# HDSC_HC32L130F8UA register map
Vendor: HDSC Co.Ltd; Series: ARMCM0P; File version: 1.2
CPU: CM0 r0p0, little endian, no MPU, no FPU, 3 interrupt priority bits
Registers are 32-bit, read-write, reset 0x0 unless marked. A register's access mark holds for its fields unless they carry their own. Offsets are from the block's base; [hi:lo] are bit positions; {n}, {i} and the like mark numbered series; 'fields as' and 'values as' point back to an identical list.

## DMAC
Base 0x40021000
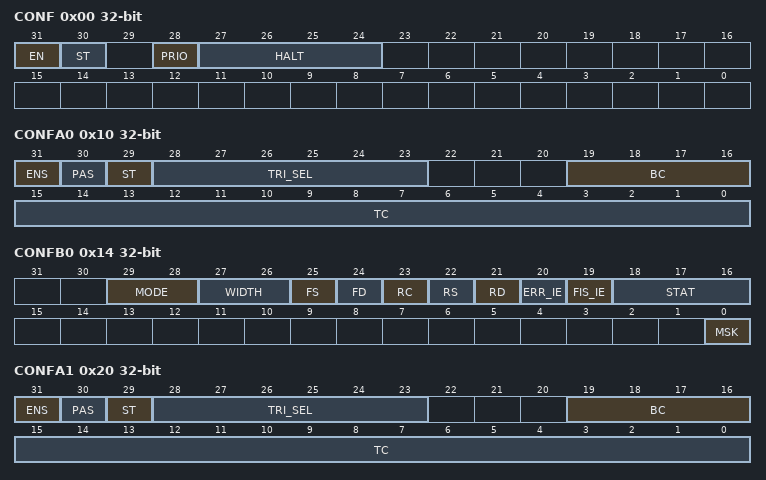
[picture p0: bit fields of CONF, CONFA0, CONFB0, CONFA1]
0x00 CONF
  [31] EN, [30] ST, [28] PRIO, [27:24] HALT
0x10 CONFA0
  [31] ENS, [30] PAS, [29] ST, [28:23] TRI_SEL, [19:16] BC, [15:0] TC
0x14 CONFB0
  [29:28] MODE, [27:26] WIDTH, [25] FS, [24] FD, [23] RC, [22] RS, [21] RD, [20] ERR_IE, [19] FIS_IE, [18:16] STAT, [0] MSK
0x18 SRCADR0
  [31:0] SRCADR
0x1C DSTADR0
  [31:0] DSTADR
0x20 CONFA1
  [31] ENS, [30] PAS, [29] ST, [28:23] TRI_SEL, [19:16] BC, [15:0] TC
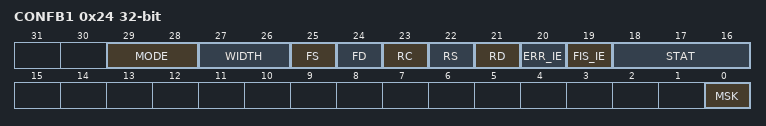
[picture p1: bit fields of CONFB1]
0x24 CONFB1
  fields as CONFB0
0x28 SRCADR1
  [31:0] SRCADR
0x2C DSTADR1
  [31:0] DSTADR

## FLASH
Base 0x40020000
0x00 TNVS reset 0x20
  [8:0] TNVS
0x04 TPGS reset 0x17
  [7:0] TPGS
0x08 TPROG reset 0x1B (reset mask 0xFF)
  [8:0] TPROG
0x0C TSERASE reset 0x4650
  [17:0] TSERASE
0x10 TMERASE reset 0x222E0
  [20:0] TMERASE
0x14 TPRCV reset 0x18
  [11:0] TPRCV
0x18 TSRCV reset 0xF0
  [11:0] TSRCV
0x1C TMRCV reset 0x3E8
  [12:0] TMRCV
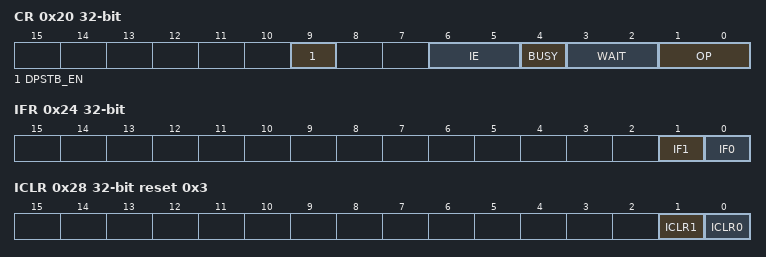
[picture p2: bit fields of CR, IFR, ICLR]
0x20 CR (reset mask 0x277)
  [9] DPSTB_EN, [6:5] IE, [4] BUSY ro, [3:2] WAIT, [1:0] OP
0x24 IFR ro
  [1] IF1, [0] IF0
0x28 ICLR wo reset 0x3
  [1] ICLR1, [0] ICLR0
0x2C BYPASS wo
  [15:0] BYSEQ
0x30 SLOCK

## HDIV
Base 0x40021800
0x00 DIVIDEND
0x04 DIVISOR reset 0x1
  [15:0] DIVISOR
0x08 QUOTIENT
0x0C REMAINDER
0x10 SIGN
  [0] SIGN
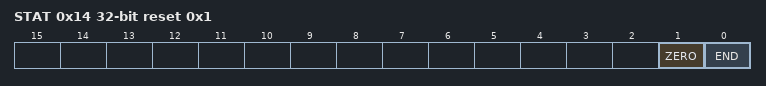
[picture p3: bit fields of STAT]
0x14 STAT reset 0x1
  [1] ZERO ro, [0] END ro

## I2C0 — desc I2C
Base 0x40000400
Same registers: I2C1 0x40004400
0x00 TMRUN
  [0] TME
0x04 TM
  [7:0] TM
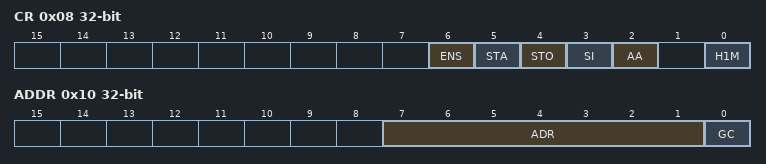
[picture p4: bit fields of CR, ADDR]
0x08 CR
  [6] ENS, [5] STA, [4] STO, [3] SI, [2] AA, [0] H1M
0x0C DATA
  [7:0] DAT
0x10 ADDR
  [7:1] ADR, [0] GC
0x14 STAT ro
  [7:0] STA

## LPTIMER
Base 0x40000F00
0x00 CNT ro
  [15:0] CNT
0x04 ARR
  [15:0] ARR
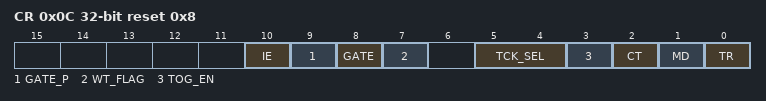
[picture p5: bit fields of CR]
0x0C CR reset 0x8
  [10] IE, [9] GATE_P, [8] GATE, [7] WT_FLAG ro, [5:4] TCK_SEL, [3] TOG_EN, [2] CT, [1] MD, [0] TR
0x10 IFR ro
  [0] TF
0x14 ICLR wo reset 0x1
  [0] TFC

## LPUART0 — desc LPUART
Base 0x40000200
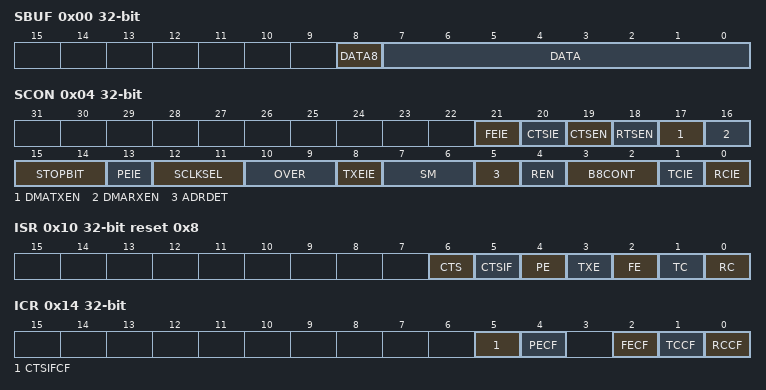
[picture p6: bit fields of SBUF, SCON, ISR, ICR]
0x00 SBUF
  [8] DATA8, [7:0] DATA
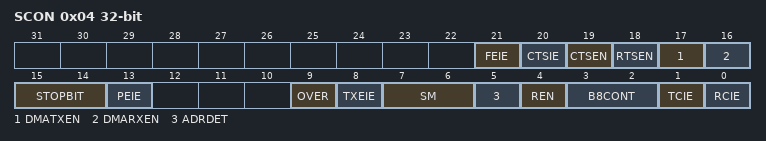
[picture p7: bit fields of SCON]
0x04 SCON
  [21] FEIE, [20] CTSIE, [19] CTSEN, [18] RTSEN, [17] DMATXEN, [16] DMARXEN, [15:14] STOPBIT, [13] PEIE, [12:11] SCLKSEL, [10:9] OVER, [8] TXEIE, [7:6] SM, [5] ADRDET, [4] REN, [3:2] B8CONT, [1] TCIE, [0] RCIE
0x08 SADDR
  [7:0] SADDR
0x0C SADEN
  [7:0] SADEN
0x10 ISR ro reset 0x8
  [6] CTS, [5] CTSIF, [4] PE, [3] TXE, [2] FE, [1] TC, [0] RC
0x14 ICR wo
  [5] CTSIFCF, [4] PECF, [2] FECF, [1] TCCF, [0] RCCF
0x18 SCNT
  [15:0] SCNT

## UART0 — desc UART
Base 0x40000000
Same registers: UART1 0x40000100
Registers as LPUART0; these are added or differ:
0x04 SCON
  [21] FEIE, [20] CTSIE, [19] CTSEN, [18] RTSEN, [17] DMATXEN, [16] DMARXEN, [15:14] STOPBIT, [13] PEIE, [9] OVER, [8] TXEIE, [7:6] SM, [5] ADRDET, [4] REN, [3:2] B8CONT, [1] TCIE, [0] RCIE

## LVD
Base 0x40002400; alternate view of ADC
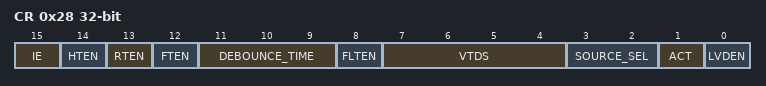
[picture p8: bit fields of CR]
0x28 CR
  [15] IE, [14] HTEN, [13] RTEN, [12] FTEN, [11:9] DEBOUNCE_TIME, [8] FLTEN, [7:4] VTDS, [3:2] SOURCE_SEL, [1] ACT, [0] LVDEN
0x2C IFR
  [0] INTF

## PCA
Base 0x40001000
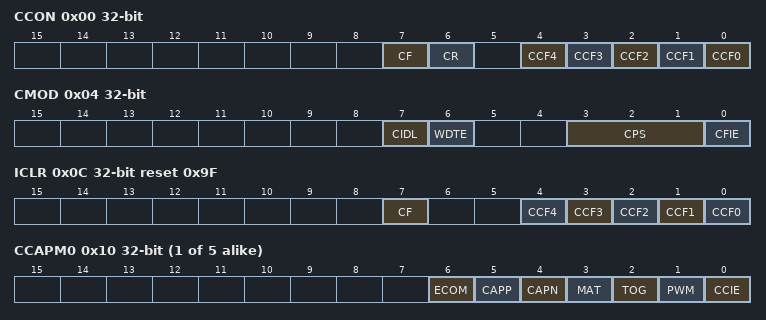
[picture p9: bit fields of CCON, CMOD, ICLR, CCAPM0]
0x00 CCON
  [7] CF, [6] CR, [n] CCF{n} (n=0..4)
0x04 CMOD
  [7] CIDL, [6] WDTE, [3:1] CPS, [0] CFIE
0x08 CNT
  [15:0] CNT
0x0C ICLR wo reset 0x9F
  [7] CF, [n] CCF{n} (n=0..4)
{0x10+4i} CCAPM{i} (i=0..4)
  [6] ECOM, [5] CAPP, [4] CAPN, [3] MAT, [2] TOG, [1] PWM, [0] CCIE
{0x24+8i} CCAP{i}H (i=0..4)
  [7:0] CCAP{i}
{0x28+8i} CCAP{i}L (i=0..4)
  [7:0] CCAP{i}
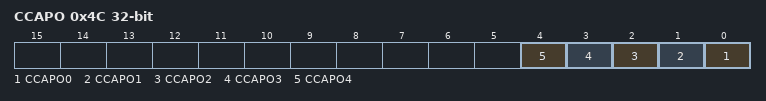
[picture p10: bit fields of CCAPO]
0x4C CCAPO
  [n] CCAPO{n} (n=0..4)
{0x50+4i} CCAP{i} (i=0..4)
  [15:0] CCAP{i}
0x64 CARR
  [15:0] CARR
0x68 EPWM
  [0] EPWM

## PCNT
Base 0x40005400
0x00 RUN 8-bit
  [0] RUN
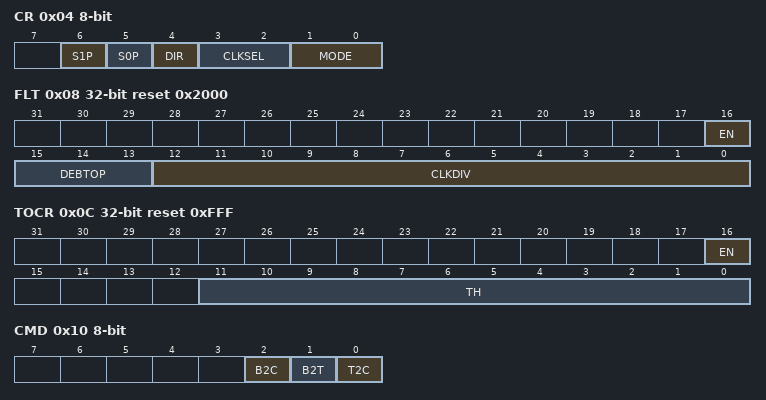
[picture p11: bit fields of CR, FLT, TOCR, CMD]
0x04 CR 8-bit
  [6] S1P, [5] S0P, [4] DIR, [3:2] CLKSEL, [1:0] MODE
0x08 FLT reset 0x2000
  [16] EN, [15:13] DEBTOP, [12:0] CLKDIV
0x0C TOCR reset 0xFFF
  [16] EN, [11:0] TH
0x10 CMD 8-bit wo
  [2] B2C, [1] B2T, [0] T2C
0x14 SR1 8-bit ro
  [0] DIR
0x18 CNT 16-bit ro
0x1C TOP 16-bit ro reset 0xFF
0x20 BUF 16-bit reset 0xFF
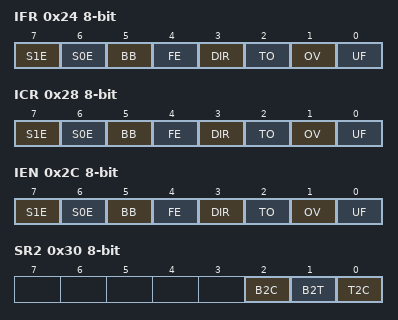
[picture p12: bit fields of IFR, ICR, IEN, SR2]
0x24 IFR 8-bit ro
  [7] S1E, [6] S0E, [5] BB, [4] FE, [3] DIR, [2] TO, [1] OV, [0] UF
0x28 ICR 8-bit wo
  [7] S1E, [6] S0E, [5] BB, [4] FE, [3] DIR, [2] TO, [1] OV, [0] UF
0x2C IEN 8-bit
  [7] S1E, [6] S0E, [5] BB, [4] FE, [3] DIR, [2] TO, [1] OV, [0] UF
0x30 SR2 8-bit ro
  [2] B2C, [1] B2T, [0] T2C
